# PIC16F1789 register map
Vendor: Microchip
Registers are 8-bit, read-write, reset 0x0 unless marked. A register's access mark holds for its fields unless they carry their own. Addresses are absolute, and some are shared; only a register's first bit layout is shown; [hi:lo] are bit positions; {n}, {i} and the like mark numbered series.

## SFR
0x00 INDF0 reset not defined — (power-on value xxxxxxxx)
0x01 INDF1 reset not defined — (power-on value xxxxxxxx)
0x02 PCL
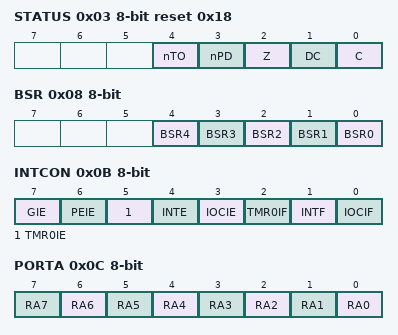
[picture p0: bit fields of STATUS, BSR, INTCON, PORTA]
0x03 STATUS reset 0x18
  [4] nTO ro, [3] nPD ro, [2] Z, [1] DC, [0] C
0x04 FSR0L
0x05 FSR0H
0x06 FSR1L
0x07 FSR1H
0x08 BSR
  [n] BSR{n} (n=0..4)
0x09 WREG
  [7:0] WREG0
0x0A PCLATH
  [6:0] PCLATH
0x0B INTCON
  [7] GIE, [6] PEIE, [5] TMR0IE, [4] INTE, [3] IOCIE, [2] TMR0IF, [1] INTF, [0] IOCIF ro
0x0C PORTA reset not defined — (power-on value xxxxxxxx)
  [n] RA{n} (n=0..7)
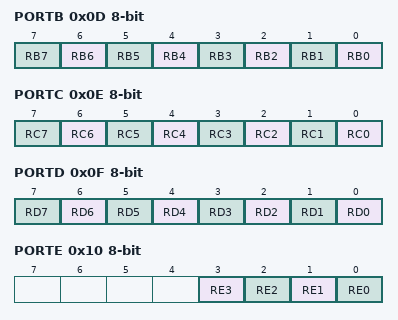
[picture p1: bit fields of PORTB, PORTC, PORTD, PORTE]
0x0D PORTB reset not defined — (power-on value xxxxxxxx)
  [n] RB{n} (n=0..7)
0x0E PORTC reset not defined — (power-on value xxxxxxxx)
  [n] RC{n} (n=0..7)
0x0F PORTD reset not defined — (power-on value xxxxxxxx)
  [n] RD{n} (n=0..7)
0x10 PORTE reset not defined — (power-on value ----xxxx)
  [3] RE3 ro, [2] RE2, [1] RE1, [0] RE0
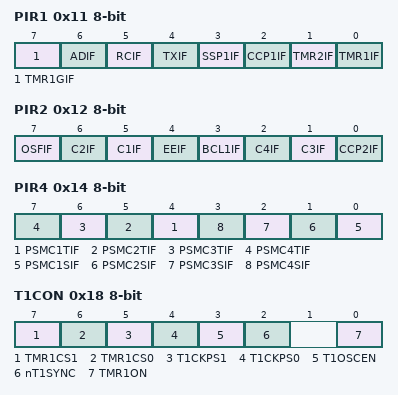
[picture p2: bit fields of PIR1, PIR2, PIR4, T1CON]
0x11 PIR1
  [7] TMR1GIF — Timer1 Gate Interrupt Flag bit
  [6] ADIF — A/D Converter Interrupt Flag bit
  [5] RCIF ro — EUSART Receive Interrupt Flag bit
  [4] TXIF ro — EUSART Transmit Interrupt Flag bit
  [3] SSP1IF — Master Synchronous Serial Port (MSSP) Interrupt Flag bit
  [2] CCP1IF — CCP1 Interrupt Flag bit
  [1] TMR2IF — TMR2 to PR2 Match Interrupt Flag bit
  [0] TMR1IF — TMR1 Overflow Interrupt Flag bit
0x12 PIR2
  [7] OSFIF, [6] C2IF, [5] C1IF, [4] EEIF, [3] BCL1IF, [2] C4IF, [1] C3IF, [0] CCP2IF
0x13 PIR3
  [4] CCP3IF
0x14 PIR4
  [n+3] PSMC{n}TIF (n=1..4), [n-1] PSMC{n}SIF (n=1..4)
0x15 TMR0 reset not defined — (power-on value xxxxxxxx)
0x16 TMR1L reset not defined — (power-on value xxxxxxxx)
0x17 TMR1H reset not defined — (power-on value xxxxxxxx)
0x18 T1CON
  [7] TMR1CS1, [6] TMR1CS0, [5] T1CKPS1, [4] T1CKPS0, [3] T1OSCEN, [2] nT1SYNC, [0] TMR1ON
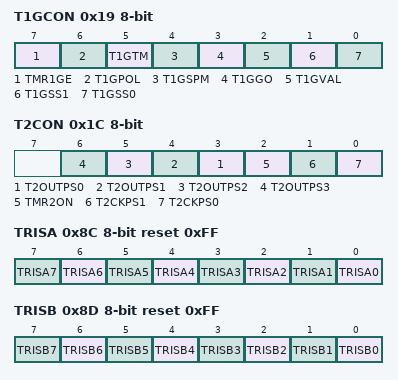
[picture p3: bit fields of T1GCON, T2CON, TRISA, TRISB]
0x19 T1GCON reset not defined — (power-on value 00000x00)
  [7] TMR1GE, [6] T1GPOL, [5] T1GTM, [4] T1GSPM, [3] T1GGO, [2] T1GVAL ro, [1] T1GSS1, [0] T1GSS0
0x1A TMR2
0x1B PR2 reset 0xFF
0x1C T2CON
  [n+3] T2OUTPS{n} (n=0..3), [2] TMR2ON, [1] T2CKPS1, [0] T2CKPS0
0x8C TRISA reset 0xFF — PORTA Data Direction Control Register
  [n] TRISA{n} (n=0..7)
0x8D TRISB reset 0xFF
  [n] TRISB{n} (n=0..7)
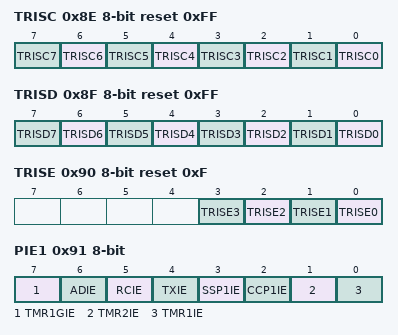
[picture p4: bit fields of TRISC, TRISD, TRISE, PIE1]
0x8E TRISC reset 0xFF — PORTB Data Direction Control Register
  [n] TRISC{n} (n=0..7)
0x8F TRISD reset 0xFF
  [n] TRISD{n} (n=0..7)
0x90 TRISE reset 0xF
  [n] TRISE{n} (n=0..3)
0x91 PIE1 — Peripheral Interrupt Enable Register 1
  [7] TMR1GIE — Timer1 Gate Interrupt Enable bit
  [6] ADIE — A/D Converter Interrupt Enable bit
  [5] RCIE — EUSART Receive Interrupt Enable bit
  [4] TXIE — EUSART Transmit Interrupt Enable bit
  [3] SSP1IE — Master Synchronous Serial Port (MSSP) Interrupt Enable bit
  [2] CCP1IE — CCP1 Interrupt Enable bit
  [1] TMR2IE — TMR2 to PR2 Match Interrupt Enable bit
  [0] TMR1IE — TMR1 Overflow Interrupt Enable bit
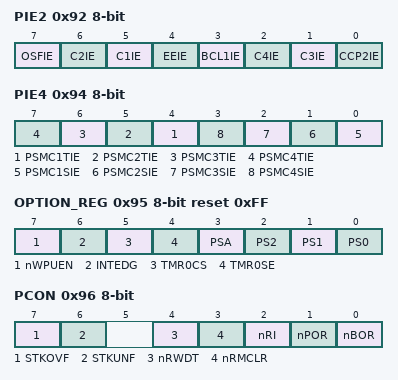
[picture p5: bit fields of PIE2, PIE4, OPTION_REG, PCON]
0x92 PIE2 — Peripheral Interrupt Enable Register 2
  [7] OSFIE — CCP2 Interrupt Enable bit
  [6] C2IE — Comparator C2 Interrupt Enable bit
  [5] C1IE — Comparator C1 Interrupt Enable bit
  [4] EEIE — EEPROM Write Completion Interrupt Enable bit
  [3] BCL1IE — MSSP Bus Collision Interrupt Interrupt Enable bit
  [2] C4IE
  [1] C3IE
  [0] CCP2IE
0x93 PIE3
  [4] CCP3IE
0x94 PIE4
  [n+3] PSMC{n}TIE (n=1..4), [n-1] PSMC{n}SIE (n=1..4)
0x95 OPTION_REG reset 0xFF — Option Register
  [7] nWPUEN — Weak Pull-up Enable bit
  [6] INTEDG — Interrupt Edge Select bit
  [5] TMR0CS — TMR0 Clock Source Select bit
  [4] TMR0SE — TMR0 Source Edge Select bit
  [3] PSA — Prescaler Active bit
  [2] PS2 — Prescaler Rate Select bits
  [1] PS1 — Prescaler Rate Select bits
  [0] PS0 — Prescaler Rate Select bits
0x96 PCON reset not defined — Power Control Register (power-on value 00-111qq)
  [7] STKOVF — Stack Overflow Flag bit
  [6] STKUNF — Stack Underflow Flag bit
  [4] nRWDT
  [3] nRMCLR — MCLR Reset Flag bit
  [2] nRI — RESET Instruction Flag bit
  [1] nPOR — Power-on Reset Status bit
  [0] nBOR — Brown-out Reset Status bit
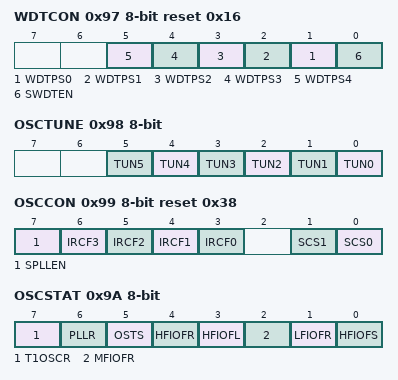
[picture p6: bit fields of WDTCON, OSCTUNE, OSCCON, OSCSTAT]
0x97 WDTCON reset 0x16 — Watchdog Timer Control Register
  [n+1] WDTPS{n} (n=0..4) — Watchdog Timer Period Select bits
  [0] SWDTEN — Software Enable/Disable for Watch Dog Timer bit
0x98 OSCTUNE — Oscillator Tuning Register
  [n] TUN{n} (n=0..5) — Frequency Tuning bits
0x99 OSCCON reset 0x38 — Oscillator Control Register
  [7] SPLLEN — Software PLL Enable bit
  [n+3] IRCF{n} (n=0..3) — Internal Oscillator Frequency Select bits
  [1] SCS1 — System clock select bit
  [0] SCS0 — System clock select bit
0x9A OSCSTAT ro reset not defined — Oscillator Status Register (power-on value 10q00q00)
  [7] T1OSCR — Timer1 Oscillator Ready bit
  [6] PLLR — 4x PLL Ready bit
  [5] OSTS — Oscillator Start-up Time-out Status bit
  [4] HFIOFR — High Freqency Internal Oscillator Ready bit
  [3] HFIOFL — High Freqency Internal Oscillator Status Locked bit
  [2] MFIOFR — Medium Freqency Internal Oscillator Ready bit
  [1] LFIOFR — Low Freqency Internal Oscillator Ready bit
  [0] HFIOFS — Low Freqency Internal Oscillator Ready bit
0x9B ADRESL reset not defined — A/D Result Register LSB (power-on value xxxxxxxx)
0x9C ADRESH reset not defined — A/D Result Register MSB (power-on value xxxxxxxx)
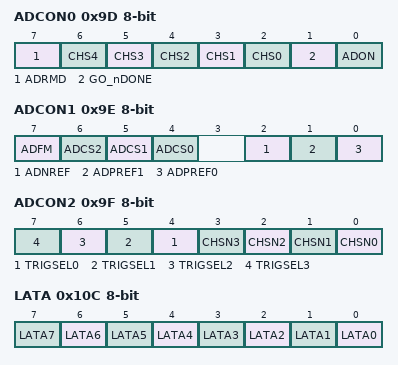
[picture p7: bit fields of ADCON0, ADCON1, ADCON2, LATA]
0x9D ADCON0 — Analog-to-Digital Control Register 0
  [7] ADRMD
  [n+2] CHS{n} (n=0..4) — Analog Channel Select bits
  [1] GO_nDONE — A/D Conversion Status bit
  [0] ADON — A/D Module Enable bit
0x9E ADCON1 — Analog-to-Digital Control Register 1
  [7] ADFM — A/D Result Format Select bit
  [6] ADCS2 — A/D Conversion Clock Select bits
  [5] ADCS1 — A/D Conversion Clock Select bits
  [4] ADCS0 — A/D Conversion Clock Select bits
  [2] ADNREF — A/D Negative Voltage Reference Configuration
  [1] ADPREF1 — A/D Positive Voltage Reference Configuration
  [0] ADPREF0 — A/D Positive Voltage Reference Configuration
0x9F ADCON2
  [n+4] TRIGSEL{n} (n=0..3), [n] CHSN{n} (n=0..3)
0x10C LATA reset not defined — (power-on value xxxxxxxx)
  [n] LATA{n} (n=0..7)
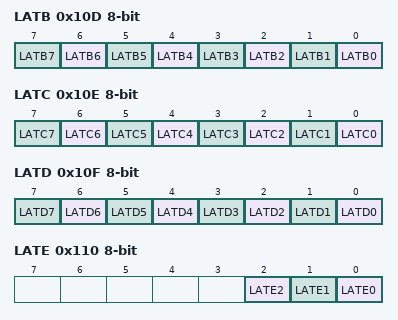
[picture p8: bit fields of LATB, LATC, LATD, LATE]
0x10D LATB reset not defined — (power-on value xxxxxxxx)
  [n] LATB{n} (n=0..7)
0x10E LATC reset not defined — (power-on value xxxxxxxx)
  [n] LATC{n} (n=0..7)
0x10F LATD reset not defined — (power-on value xxxxxxxx)
  [n] LATD{n} (n=0..7)
0x110 LATE reset not defined — (power-on value -----xxx)
  [2] LATE2, [1] LATE1, [0] LATE0
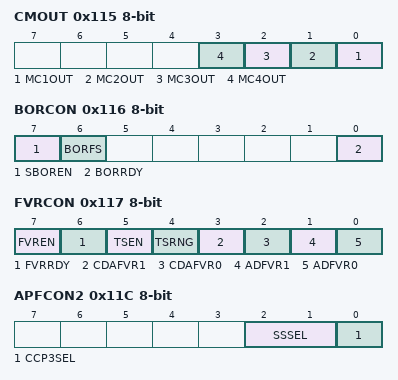
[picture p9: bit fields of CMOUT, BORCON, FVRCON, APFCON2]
0x115 CMOUT ro — Comparator Output Register
  [n-1] MC{n}OUT (n=1..4)
0x116 BORCON reset not defined — Brown-out Reset Control Register (power-on value 10-----q)
  [7] SBOREN — Software Brown Out Reset Enable bit
  [6] BORFS
  [0] BORRDY ro — Brown-out Reset Circuit Ready Status bit
0x117 FVRCON reset not defined — Fixed Voltage Reference Control Register (power-on value 0q000000)
  [7] FVREN — Fixed Voltage Reference Enable
  [6] FVRRDY ro — Fixed Voltage Reference Ready Flag
  [5] TSEN
  [4] TSRNG
  [3] CDAFVR1 — Comparator and D/A Converter Fixed Voltage Reference Selection
  [2] CDAFVR0 — Comparator and D/A Converter Fixed Voltage Reference Selection
  [1] ADFVR1 — A/D Converter Fixed Voltage Reference Selection
  [0] ADFVR0 — A/D Converter Fixed Voltage Reference Selection
0x11C APFCON2
  [2:1] SSSEL, [0] CCP3SEL
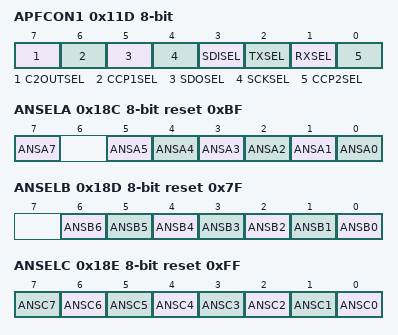
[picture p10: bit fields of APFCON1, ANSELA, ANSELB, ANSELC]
0x11D APFCON1 — Alternate Pin Function Control Register
  [7] C2OUTSEL, [6] CCP1SEL, [5] SDOSEL, [4] SCKSEL, [3] SDISEL, [2] TXSEL, [1] RXSEL, [0] CCP2SEL
0x18C ANSELA reset 0xBF
  [7] ANSA7, [n] ANSA{n} (n=0..5)
0x18D ANSELB reset 0x7F
  [n] ANSB{n} (n=0..6)
0x18E ANSELC reset 0xFF
  [n] ANSC{n} (n=0..7)
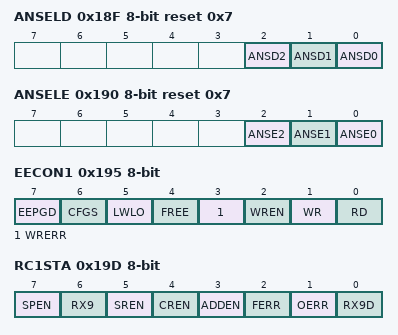
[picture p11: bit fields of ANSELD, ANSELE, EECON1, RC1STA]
0x18F ANSELD reset 0x7
  [2] ANSD2, [1] ANSD1, [0] ANSD0
0x190 ANSELE reset 0x7
  [2] ANSE2, [1] ANSE1, [0] ANSE0
0x191 EEADRL
0x192 EEADRH reset 0x80
  [6:0] EEADRH
0x193 EEDATL reset not defined — (power-on value xxxxxxxx)
0x194 EEDATH reset not defined — (power-on value --xxxxxx)
  [5:0] EEDATH
0x195 EECON1 reset not defined — (power-on value 0000x000)
  [7] EEPGD — FLASH Program / Data EEPROM Memory Select bit
  [6] CFGS — FLASH Program / Data EEPROM or Configuration Select bit
  [5] LWLO — Load Write Latches Only bit
  [4] FREE — Program FLASH Erase Enable bit
  [3] WRERR — Sequence Error Flag bit
  [2] WREN — Program/Erase Enable bit
  [1] WR — Write Control bit (can only be set)
  [0] RD — Read Control bit (can only be set)
0x196 EECON2 wo
0x197 VREGCON reset 0x1
  [1] VREGPM
0x199 RC1REG ro
0x19A TX1REG
0x19B SP1BRGL
0x19C SP1BRGH
0x19D RC1STA
  [7] SPEN, [6] RX9, [5] SREN, [4] CREN, [3] ADDEN, [2] FERR ro, [1] OERR ro, [0] RX9D ro
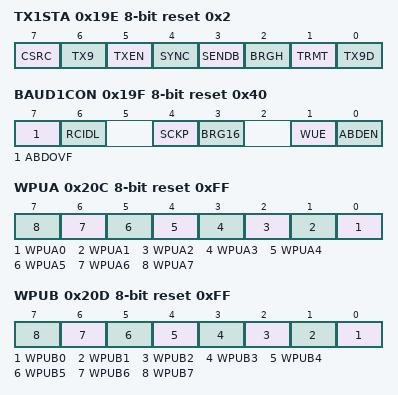
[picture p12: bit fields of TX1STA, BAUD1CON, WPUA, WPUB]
0x19E TX1STA reset 0x2
  [7] CSRC, [6] TX9, [5] TXEN, [4] SYNC, [3] SENDB, [2] BRGH, [1] TRMT ro, [0] TX9D
0x19F BAUD1CON reset 0x40
  [7] ABDOVF ro, [6] RCIDL ro, [4] SCKP, [3] BRG16, [1] WUE, [0] ABDEN
0x20C WPUA reset 0xFF
  [n] WPUA{n} (n=0..7)
0x20D WPUB reset 0xFF
  [n] WPUB{n} (n=0..7)
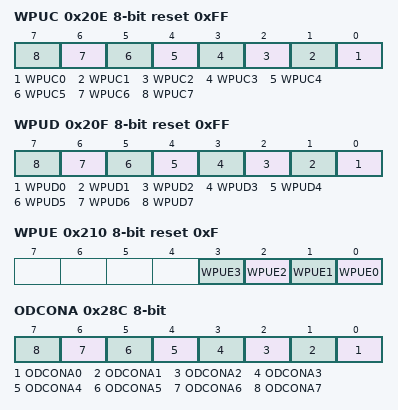
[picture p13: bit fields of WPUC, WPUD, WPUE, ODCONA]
0x20E WPUC reset 0xFF
  [n] WPUC{n} (n=0..7)
0x20F WPUD reset 0xFF
  [n] WPUD{n} (n=0..7)
0x210 WPUE reset 0xF
  [n] WPUE{n} (n=0..3)
0x28C ODCONA
  [n] ODCONA{n} (n=0..7)
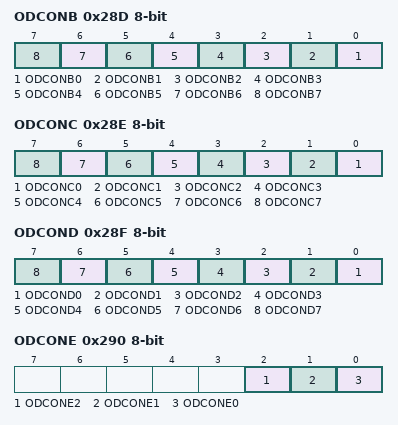
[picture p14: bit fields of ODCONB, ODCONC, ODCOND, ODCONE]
0x28D ODCONB
  [n] ODCONB{n} (n=0..7)
0x28E ODCONC
  [n] ODCONC{n} (n=0..7)
0x28F ODCOND
  [n] ODCOND{n} (n=0..7)
0x290 ODCONE
  [2] ODCONE2, [1] ODCONE1, [0] ODCONE0
0x30C SLRCONA
  [n] SLRCONA{n} (n=0..7)
0x30D SLRCONB
  [n] SLRCONB{n} (n=0..7)
0x30E SLRCONC
  [n] SLRCONC{n} (n=0..7)
0x30F SLRCOND
  [n] SLRCOND{n} (n=0..7)
0x310 SLRCONE
  [2] SLRCONE2, [1] SLRCONE1, [0] SLRCONE0
0x38C INLVLA
  [n] INLVLA{n} (n=0..7)
0x38D INLVLB
  [n] INLVLB{n} (n=0..7)
0x38E INLVLC reset 0xFF
  [n] INLVLC{n} (n=0..7)
0x38F INLVLD reset 0xFF
  [n] INLVLD{n} (n=0..7)
0x390 INLVLE reset 0xF
  [n] INLVLE{n} (n=0..3)
0x391 IOCAP — Interrupt-On-Change Positive Edge Register
  [n] IOCAP{n} (n=0..7)
0x392 IOCAN — Interrupt-On-Change Negative Edge Register
  [n] IOCAN{n} (n=0..7)
0x393 IOCAF — Interrupt-On-Change Flag Register
  [n] IOCAF{n} (n=0..7)
0x394 IOCBP — Interrupt-On-Change Positive Edge Register
  [n] IOCBP{n} (n=0..7)
0x395 IOCBN — Interrupt-On-Change Negative Edge Register
  [n] IOCBN{n} (n=0..7)
0x396 IOCBF — Interrupt-On-Change Flag Register
  [n] IOCBF{n} (n=0..7)
0x397 IOCCP
  [n] IOCCP{n} (n=0..7)
0x398 IOCCN
  [n] IOCCN{n} (n=0..7)
0x399 IOCCF
  [n] IOCCF{n} (n=0..7)
0x39D IOCEP
  [3] IOCEP3
0x39E IOCEN
  [3] IOCEN3
0x39F IOCEF
  [3] IOCEF3
0x51A CLKRCON reset 0x30
  [7] CLKREN, [6] CLKROE, [5] CLKRSLR, [4] CLKRDC1, [3] CLKRDC0, [2] CLKRDIV2, [1] CLKRDIV1, [0] CLKRDIV0
{0xE71+0x20*i} PSMC{i}CON (i=1..3)
  [7] PSMC{i}EN, [6] PSMC{i}LD, [5] P{i}DBFE, [4] P{i}DBRE, [3:0] P{i}MODE
{0xE72+0x20*i} PSMC{i}MDL (i=1..3)
  [7] P{i}MDLEN, [6] P{i}MDLPOL, [5] P{i}MDLBIT, [3:0] P{i}MSRC
{0xE73+0x20*i} PSMC{i}SYNC reset not defined (i=1..3) — (power-on value xxx--000)
  [7] P{i}POFST, [6] P{i}PRPOL, [5] P{i}DCPOL, [2] P{i}SYNC2, [1] P{i}SYNC1, [0] P{i}SYNC0
{0xE74+0x20*i} PSMC{i}CLK (i=1..3)
  [5] P{i}CPRE1, [4] P{i}CPRE0, [1] P{i}CSRC1, [0] P{i}CSRC0
0xE95 PSMC1OEN
  [5] P1OEF, [4] P1OEE, [3] P1OED, [2] P1OEC, [1] P1OEB, [0] P1OEA
0xE96 PSMC1POL
  [6] P1INPOL, [5] P1POLF, [4] P1POLE, [3] P1POLD, [2] P1POLC, [1] P1POLB, [0] P1POLA
{0xE77+0x20*i} PSMC{i}BLNK (i=1..3)
  [5:4] P{i}FEBM, [1:0] P{i}REBM
{0xE78+0x20*i} PSMC{i}REBS (i=1..3)
  [7] P{i}REBSIN, [n] P{i}REBSC{n} (n=1..4)
{0xE79+0x20*i} PSMC{i}FEBS (i=1..3)
  [7] P{i}FEBSIN, [n] P{i}FEBSC{n} (n=1..4)
{0xE7A+0x20*i} PSMC{i}PHS (i=1..3)
  [7] P{i}PHSIN, [n] P{i}PHSC{n} (n=1..4), [0] P{i}PHST
{0xE7B+0x20*i} PSMC{i}DCS (i=1..3)
  [7] P{i}DCSIN, [n] P{i}DCSC{n} (n=1..4), [0] P{i}DCST
{0xE7C+0x20*i} PSMC{i}PRS (i=1..3)
  [7] P{i}PRSIN, [n] P{i}PRSC{n} (n=1..4), [0] P{i}PRST
{0xE7D+0x20*i} PSMC{i}ASDC (i=1..3)
  [7] P{i}ASE, [6] P{i}ASDEN, [5] P{i}ARSEN, [0] P{i}ASDOV
0xE9E PSMC1ASDL
  [5] P1ASDLF, [4] P1ASDLE, [3] P1ASDLD, [2] P1ASDLC, [1] P1ASDLB, [0] P1ASDLA
{0xE7F+0x20*i} PSMC{i}ASDS (i=1..3)
  [7] P{i}ASDSIN, [n] P{i}ASDSC{n} (n=1..4)
{0xE80+0x20*i} PSMC{i}INT (i=1..3)
  [7] P{i}TOVIE, [6] P{i}TPHIE, [5] P{i}TDCIE, [4] P{i}TPRIE, [3] P{i}TOVIF, [2] P{i}TPHIF, [1] P{i}TDCIF, [0] P{i}TPRIF
{0xE81+0x20*i} PSMC{i}PHL (i=1..3)
  [n] PSMC{i}PH{n} (n=0..7)
{0xE82+0x20*i} PSMC{i}PHH (i=1..3)
  [n-8] PSMC{i}PH{n} (n=8..15)
{0xE83+0x20*i} PSMC{i}DCL (i=1..3)
  [n] PSMC{i}DC{n} (n=0..7)
{0xE84+0x20*i} PSMC{i}DCH (i=1..3)
  [n-8] PSMC{i}DC{n} (n=8..15)
{0xE85+0x20*i} PSMC{i}PRL (i=1..3)
  [n] PSMC{i}PR{n} (n=0..7)
{0xE86+0x20*i} PSMC{i}PRH (i=1..3)
  [n-8] PSMC{i}PR{n} (n=8..15)
{0xE87+0x20*i} PSMC{i}TMRL reset 0x1 (i=1..3)
  [n] PSMC{i}TMR{n} (n=0..7)
{0xE88+0x20*i} PSMC{i}TMRH (i=1..3)
  [n-8] PSMC{i}TMR{n} (n=8..15)
{0xE89+0x20*i} PSMC{i}DBR (i=1..3)
  [n] PSMC{i}DBR{n} (n=0..7)
{0xE8A+0x20*i} PSMC{i}DBF (i=1..3)
  [n] PSMC{i}DBF{n} (n=0..7)
{0xE8B+0x20*i} PSMC{i}BLKR (i=1..3)
  [n] PSMC{i}BLKR{n} (n=0..7)
{0xE8C+0x20*i} PSMC{i}BLKF (i=1..3)
  [n] PSMC{i}BLKF{n} (n=0..7)
{0xE8D+0x20*i} PSMC{i}FFA (i=1..3)
  [n] PSMC{i}FFA{n} (n=0..3)
0xEAE PSMC1STR0 reset 0x1
  [5] P1STRF, [4] P1STRE, [3] P1STRD, [2] P1STRC, [1] P1STRB, [0] P1STRA
{0xE8F+0x20*i} PSMC{i}STR1 (i=1..3)
  [7] P{i}SSYNC, [1] P{i}LSMEN, [0] P{i}HSMEN
0xEB5 PSMC2OEN
  [1] P2OEB, [0] P2OEA
0xEB6 PSMC2POL
  [6] P2INPOL, [1] P2POLB, [0] P2POLA
0xEBE PSMC2ASDL
  [1] P2ASDLB, [0] P2ASDLA
0xECE PSMC2STR0 reset 0x1
  [1] P2STRB, [0] P2STRA
0xED5 PSMC3OEN
  [5] P3OEF, [4] P3OEE, [3] P3OED, [2] P3OEC, [1] P3OEB, [0] P3OEA
0xED6 PSMC3POL
  [6] P3INPOL, [5] P3POLF, [4] P3POLE, [3] P3POLD, [2] P3POLC, [1] P3POLB, [0] P3POLA
0xEDE PSMC3ASDL
  [5] P3ASDLF, [4] P3ASDLE, [3] P3ASDLD, [2] P3ASDLC, [1] P3ASDLB, [0] P3ASDLA
0xEEE PSMC3STR0 reset 0x1
  [5] P3STRF, [4] P3STRE, [3] P3STRD, [2] P3STRC, [1] P3STRB, [0] P3STRA
0xF11 PSMC4CON
  [7] PSMC4EN, [6] PSMC4LD, [5] P4DBFE, [4] P4DBRE, [3:0] P4MODE
0xF12 PSMC4MDL
  [7] P4MDLEN, [6] P4MDLPOL, [5] P4MDLBIT, [3:0] P4MSRC
0xF13 PSMC4SYNC reset not defined — (power-on value xxx--000)
  [7] P4POFST, [6] P4PRPOL, [5] P4DCPOL, [2] P4SYNC2, [1] P4SYNC1, [0] P4SYNC0
0xF14 PSMC4CLK
  [5] P4CPRE1, [4] P4CPRE0, [1] P4CSRC1, [0] P4CSRC0
0xF15 PSMC4OEN
  [1] P4OEB, [0] P4OEA
0xF16 PSMC4POL
  [6] P4INPOL, [1] P4POLB, [0] P4POLA
0xF17 PSMC4BLNK
  [5:4] P4FEBM, [1:0] P4REBM
0xF18 PSMC4REBS
  [7] P4REBSIN, [n] P4REBSC{n} (n=1..4)
0xF19 PSMC4FEBS
  [7] P4FEBSIN, [n] P4FEBSC{n} (n=1..4)
0xF1A PSMC4PHS
  [7] P4PHSIN, [n] P4PHSC{n} (n=1..4), [0] P4PHST
0xF1B PSMC4DCS
  [7] P4DCSIN, [n] P4DCSC{n} (n=1..4), [0] P4DCST
0xF1C PSMC4PRS
  [7] P4PRSIN, [n] P4PRSC{n} (n=1..4), [0] P4PRST
0xF1D PSMC4ASDC
  [7] P4ASE, [6] P4ASDEN, [5] P4ARSEN, [0] P4ASDOV
0xF1E PSMC4ASDL
  [1] P4ASDLB, [0] P4ASDLA
0xF1F PSMC4ASDS
  [7] P4ASDSIN, [n] P4ASDSC{n} (n=1..4)
0xF20 PSMC4INT
  [7] P4TOVIE, [6] P4TPHIE, [5] P4TDCIE, [4] P4TPRIE, [3] P4TOVIF, [2] P4TPHIF, [1] P4TDCIF, [0] P4TPRIF
0xF21 PSMC4PHL
  [n] PSMC4PH{n} (n=0..7)
0xF22 PSMC4PHH
  [n-8] PSMC4PH{n} (n=8..15)
0xF23 PSMC4DCL
  [n] PSMC4DC{n} (n=0..7)
0xF24 PSMC4DCH
  [n-8] PSMC4DC{n} (n=8..15)
0xF25 PSMC4PRL
  [n] PSMC4PR{n} (n=0..7)
0xF26 PSMC4PRH
  [n-8] PSMC4PR{n} (n=8..15)
0xF27 PSMC4TMRL reset 0x1
  [n] PSMC4TMR{n} (n=0..7)
0xF28 PSMC4TMRH
  [n-8] PSMC4TMR{n} (n=8..15)
0xF29 PSMC4DBR
  [n] PSMC4DBR{n} (n=0..7)
0xF2A PSMC4DBF
  [n] PSMC4DBF{n} (n=0..7)
0xF2B PSMC4BLKR
  [n] PSMC4BLKR{n} (n=0..7)
0xF2C PSMC4BLKF
  [n] PSMC4BLKF{n} (n=0..7)
0xF2D PSMC4FFA
  [n] PSMC4FFA{n} (n=0..3)
0xF2E PSMC4STR0 reset 0x1
  [1] P4STRB, [0] P4STRA
0xF2F PSMC4STR1
  [7] P4SSYNC, [1] P4LSMEN, [0] P4HSMEN
0xFE4 STATUS_SHAD reset not defined — (power-on value -----xxx)
  [2] Z_SHAD, [1] DC_SHAD, [0] C_SHAD
0xFE5 WREG_SHAD reset not defined — (power-on value xxxxxxxx)
0xFE6 BSR_SHAD reset not defined — (power-on value ---xxxxx)
  [4:0] BSR_SHAD
0xFE7 PCLATH_SHAD reset not defined — (power-on value -xxxxxxx)
  [6:0] PCLATH_SHAD
0xFE8 FSR0L_SHAD reset not defined — (power-on value xxxxxxxx)
0xFE9 FSR0H_SHAD reset not defined — (power-on value xxxxxxxx)
0xFEA FSR1L_SHAD reset not defined — (power-on value xxxxxxxx)
0xFEB FSR1H_SHAD reset not defined — (power-on value xxxxxxxx)
0xFED STKPTR reset 0x1F — Current Stack pointer
  [4:0] STKPTR
0xFEE TOSL reset not defined — Top of Stack Low byte (power-on value xxxxxxxx)
0xFEF TOSH reset not defined — Top of Stack High byte (power-on value -xxxxxxx)
  [6:0] TOSH
